AUTOSAR XML (schema 4-0-3)
standard types defined: uint8, Boolean, UInt16, UInt32, UInt8
package /AUTOSAR_Platform/DataConstrs
  range DC_Boolean: raw 0..1
  range DC_UInt16: raw 0..65535
  range DC_UInt8: raw 0..255
package /PATAC/Facility/DataTypes/Implementation
  compu method COMPU_Boolean: 0=FALSE, 1=TRUE
  unit NoUnit: factor-si-to-unit=1, offset-si-to-unit=0
package /PATAC/MSM/ComponentTypes
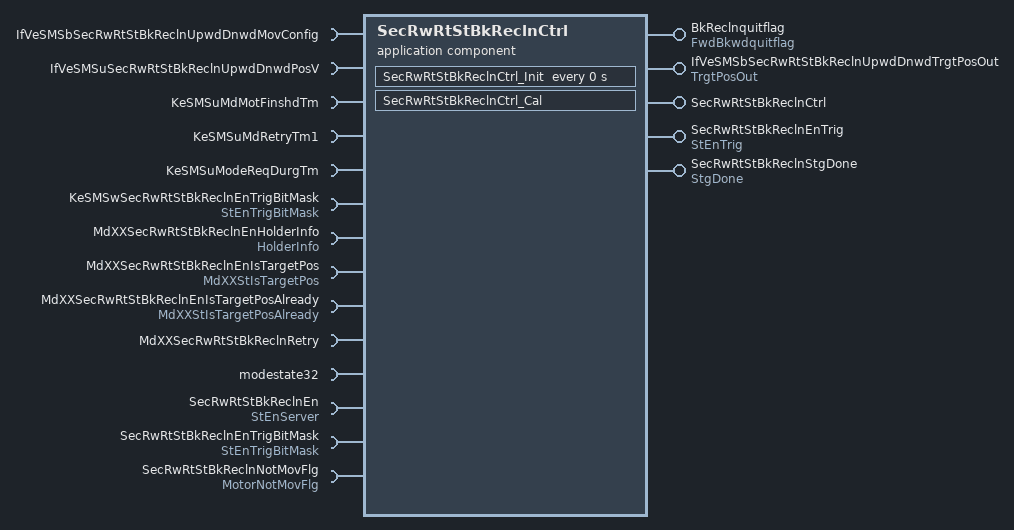
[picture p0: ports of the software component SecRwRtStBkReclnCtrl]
  application sw component type SecRwRtStBkReclnCtrl
    5 x provide port:
      BkReclnquitflag: nonqueued-sender-com-spec{data-element=FwdBkwdquitflag/Val, init-value=0}, provided-interface=FwdBkwdquitflag
      IfVeSMSbSecRwRtStBkReclnUpwdDnwdTrgtPosOut: nonqueued-sender-com-spec{data-element=TrgtPosOut/Val, init-value=0}, provided-interface=TrgtPosOut
      SecRwRtStBkReclnCtrl: server-com-spec{operation=Cal, queue-length=1}, provided-interface=SecRwRtStBkReclnCtrl
      SecRwRtStBkReclnEnTrig: nonqueued-sender-com-spec{data-element=StEnTrig/Val, init-value=0}, provided-interface=StEnTrig
      SecRwRtStBkReclnStgDone: nonqueued-sender-com-spec{data-element=StgDone/Val, init-value=0}, provided-interface=StgDone
    14 x require port:
      IfVeSMSbSecRwRtStBkReclnUpwdDnwdMovConfig: nonqueued-receiver-com-spec{data-element=IfVeSMSbSecRwRtStBkReclnUpwdDnwdMovConfig/Val, filter=data-filter-type=ALWAYS, init-value=0}, required-interface=IfVeSMSbSecRwRtStBkReclnUpwdDnwdMovConfig
      IfVeSMSuSecRwRtStBkReclnUpwdDnwdPosV: nonqueued-receiver-com-spec{data-element=IfVeSMSuSecRwRtStBkReclnUpwdDnwdPosV/Val, filter=data-filter-type=ALWAYS, init-value=0}, required-interface=IfVeSMSuSecRwRtStBkReclnUpwdDnwdPosV
      KeSMSuMdMotFinshdTm: parameter-require-com-spec{init-value=0, parameter=KeSMSuMdMotFinshdTm/Val}, required-interface=KeSMSuMdMotFinshdTm
      KeSMSuMdRetryTm1: parameter-require-com-spec{init-value=0, parameter=KeSMSuMdRetryTm1/Val}, required-interface=KeSMSuMdRetryTm1
      KeSMSuModeReqDurgTm: parameter-require-com-spec{init-value=0, parameter=KeSMSuModeReqDurgTm/Val}, required-interface=KeSMSuModeReqDurgTm
      KeSMSwSecRwRtStBkReclnEnTrigBitMask: parameter-require-com-spec{init-value=6153, parameter=StEnTrigBitMask/Val}, required-interface=StEnTrigBitMask
      MdXXSecRwRtStBkReclnEnHolderInfo: nonqueued-receiver-com-spec{data-element=HolderInfo/Val, filter=data-filter-type=ALWAYS, init-value=0}, required-interface=HolderInfo
      MdXXSecRwRtStBkReclnEnIsTargetPos: nonqueued-receiver-com-spec{data-element=MdXXStIsTargetPos/Val, filter=data-filter-type=ALWAYS, init-value=0}, required-interface=MdXXStIsTargetPos
      MdXXSecRwRtStBkReclnEnIsTargetPosAlready: nonqueued-receiver-com-spec{data-element=MdXXStIsTargetPosAlready/Val, filter=data-filter-type=ALWAYS, init-value=0}, required-interface=MdXXStIsTargetPosAlready
      MdXXSecRwRtStBkReclnRetry: nonqueued-receiver-com-spec{data-element=MdXXSecRwRtStBkReclnRetry/Val, filter=data-filter-type=ALWAYS, init-value=0}, required-interface=MdXXSecRwRtStBkReclnRetry
      modestate32: nonqueued-receiver-com-spec{data-element=modestate32/Val, filter=data-filter-type=ALWAYS, init-value=0}, required-interface=modestate32
      SecRwRtStBkReclnEn: required-com-specs=[Clear, Get, Set], required-interface=StEnServer
      SecRwRtStBkReclnEnTrigBitMask: nonqueued-receiver-com-spec{data-element=StEnTrigBitMask/Val, filter=data-filter-type=ALWAYS, init-value=0}, required-interface=StEnTrigBitMask
      SecRwRtStBkReclnNotMovFlg: nonqueued-receiver-com-spec{data-element=MotorNotMovFlg/Val, filter=data-filter-type=ALWAYS, init-value=0}, required-interface=MotorNotMovFlg
    behavior SecRwRtStBkReclnCtrl_InternalBehavior
      operation invoked event OIT_SecRwRtStBkReclnCtrl_Cal_SecRwRtStBkReclnCtrl_Cal: start-on-event=SecRwRtStBkReclnCtrl_Cal, operation=SecRwRtStBkReclnCtrl.Cal
      timing event SecRwRtStBkReclnCtrl_InitEvent: start-on-event=SecRwRtStBkReclnCtrl_Init, period=0
      runnable SecRwRtStBkReclnCtrl_Cal
        data-receive-point-by-arguments:
          9 x access:
            REC_IfVeSMSbSecRwRtStBkReclnUpwdDnwdMovConfig_Val: accessed-variable=IfVeSMSbSecRwRtStBkReclnUpwdDnwdMovConfig.Val
            REC_IfVeSMSuSecRwRtStBkReclnUpwdDnwdPosV_Val: accessed-variable=IfVeSMSuSecRwRtStBkReclnUpwdDnwdPosV.Val
            REC_MdXXSecRwRtStBkReclnEnHolderInfo_Val: accessed-variable=MdXXSecRwRtStBkReclnEnHolderInfo.Val
            REC_MdXXSecRwRtStBkReclnEnIsTargetPos_Val: accessed-variable=MdXXSecRwRtStBkReclnEnIsTargetPos.Val
            REC_MdXXSecRwRtStBkReclnEnIsTargetPosAlready_Val: accessed-variable=MdXXSecRwRtStBkReclnEnIsTargetPosAlready.Val
            REC_MdXXSecRwRtStBkReclnRetry_Val: accessed-variable=MdXXSecRwRtStBkReclnRetry.Val
            REC_modestate32_Val: accessed-variable=modestate32.Val
            REC_SecRwRtStBkReclnEnTrigBitMask_Val: accessed-variable=SecRwRtStBkReclnEnTrigBitMask.Val
            REC_SecRwRtStBkReclnNotMovFlg_Val: accessed-variable=SecRwRtStBkReclnNotMovFlg.Val
        data-send-points:
          4 x access:
            SEND_BkReclnquitflag_Val: accessed-variable=BkReclnquitflag.Val
            SEND_IfVeSMSbSecRwRtStBkReclnUpwdDnwdTrgtPosOut_Val: accessed-variable=IfVeSMSbSecRwRtStBkReclnUpwdDnwdTrgtPosOut.Val
            SEND_SecRwRtStBkReclnEnTrig_Val: accessed-variable=SecRwRtStBkReclnEnTrig.Val
            SEND_SecRwRtStBkReclnStgDone_Val: accessed-variable=SecRwRtStBkReclnStgDone.Val
        4 x parameter access:
          PA_KeSMSuMdMotFinshdTm_Val: accessed-parameter=KeSMSuMdMotFinshdTm.Val
          PA_KeSMSuMdRetryTm1_Val: accessed-parameter=KeSMSuMdRetryTm1.Val
          PA_KeSMSuModeReqDurgTm_Val: accessed-parameter=KeSMSuModeReqDurgTm.Val
          PA_KeSMSwSecRwRtStBkReclnEnTrigBitMask_Val: accessed-parameter=KeSMSwSecRwRtStBkReclnEnTrigBitMask.Val
        sync call SC_SecRwRtStBkReclnEn_Get: operation=SecRwRtStBkReclnEn.Get, timeout=0
      runnable SecRwRtStBkReclnCtrl_Init
        4 x parameter access:
          PA_KeSMSuMdMotFinshdTm_Val: accessed-parameter=KeSMSuMdMotFinshdTm.Val
          PA_KeSMSuMdRetryTm1_Val: accessed-parameter=KeSMSuMdRetryTm1.Val
          PA_KeSMSuModeReqDurgTm_Val: accessed-parameter=KeSMSuModeReqDurgTm.Val
          PA_KeSMSwSecRwRtStBkReclnEnTrigBitMask_Val: accessed-parameter=KeSMSwSecRwRtStBkReclnEnTrigBitMask.Val
  swc implementation SecRwRtStBkReclnCtrl_Implementation: behavior=SecRwRtStBkReclnCtrl_InternalBehavior
    code-descriptors:
      code Default: artifact-descriptors=autosar-engineering-object={short-label=Default, category=SWSRC}
package /PATAC/MSM/ModeAdjust/CalPortInterface
  parameter interface KeSMSuMdMotFinshdTm
    parameter data prototype Val: sw-calibration-access=READ-WRITE, type=UInt16
  parameter interface KeSMSuModeReqDurgTm
    parameter data prototype Val: sw-calibration-access=READ-WRITE, type=UInt16
  parameter interface StEnTrigBitMask
    parameter data prototype Val: sw-calibration-access=READ-WRITE, type=UInt32
package /PATAC/MSM/ModeAdjust/Interfaces
  sender receiver interface IfVeSMSuSecRwRtStBkReclnUpwdDnwdPosV: invalidation-policy{data-element=IfVeSMSuSecRwRtStBkReclnUpwdDnwdPosV/Val, handle-invalid=DONT-INVALIDATE}
    data Val: type=Boolean
package /PATAC/MSM/ModeAdjust/PortInterface
  client server interface SecRwRtStBkReclnCtrl
    operation Cal
  client server interface StEnServer
    operation Clear
      arg data: type=UInt8, direction=IN, server-argument-impl-policy=USE-ARGUMENT-TYPE
    operation Get
      arg data: type=UInt32, direction=OUT, server-argument-impl-policy=USE-ARGUMENT-TYPE
    operation Set
      arg data: type=UInt8, direction=IN, server-argument-impl-policy=USE-ARGUMENT-TYPE
  11 x sender receiver interface:
    FwdBkwdquitflag: invalidation-policy{data-element=FwdBkwdquitflag/Val, handle-invalid=DONT-INVALIDATE}
      data Val: type=Boolean
    HolderInfo: invalidation-policy{data-element=HolderInfo/Val, handle-invalid=DONT-INVALIDATE}
      data Val: type=UInt32
    MdXXSecRwRtStBkReclnRetry: invalidation-policy{data-element=MdXXSecRwRtStBkReclnRetry/Val, handle-invalid=DONT-INVALIDATE}
      data Val: type=UInt32
    MdXXStIsTargetPos: invalidation-policy{data-element=MdXXStIsTargetPos/Val, handle-invalid=DONT-INVALIDATE}
      data Val: type=UInt32
    MdXXStIsTargetPosAlready: invalidation-policy{data-element=MdXXStIsTargetPosAlready/Val, handle-invalid=DONT-INVALIDATE}
      data Val: type=UInt32
    modestate32: invalidation-policy{data-element=modestate32/Val, handle-invalid=DONT-INVALIDATE}
      data Val: type=UInt32
    MotorNotMovFlg: invalidation-policy{data-element=MotorNotMovFlg/Val, handle-invalid=DONT-INVALIDATE}
      data Val: type=Boolean
    StEnTrig: invalidation-policy{data-element=StEnTrig/Val, handle-invalid=DONT-INVALIDATE}
      data Val: type=Boolean
    StEnTrigBitMask: invalidation-policy{data-element=StEnTrigBitMask/Val, handle-invalid=DONT-INVALIDATE}
      data Val: type=UInt32
    StgDone: invalidation-policy{data-element=StgDone/Val, handle-invalid=DONT-INVALIDATE}
      data Val: type=Boolean
    TrgtPosOut: invalidation-policy{data-element=TrgtPosOut/Val, handle-invalid=DONT-INVALIDATE}
      data Val: type=Boolean
package /PATAC/MSM/PortInterfaces
  parameter interface KeSMSuMdRetryTm1
    parameter data prototype Val: sw-calibration-access=READ-WRITE, type=UInt8
  sender receiver interface IfVeSMSbSecRwRtStBkReclnUpwdDnwdMovConfig: invalidation-policy{data-element=IfVeSMSbSecRwRtStBkReclnUpwdDnwdMovConfig/Val, handle-invalid=DONT-INVALIDATE}
    data Val: type=Boolean
